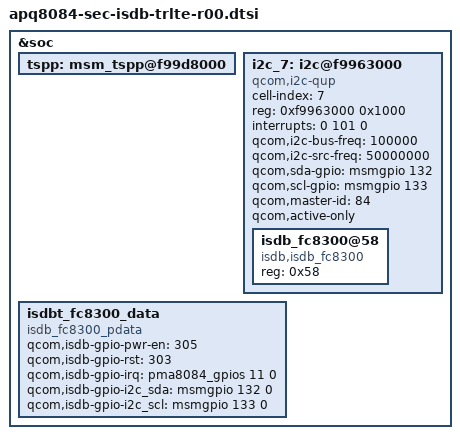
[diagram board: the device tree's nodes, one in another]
/* Copyright (c) 2012-2014, The Linux Foundation. All rights reserved.
 *
 * This program is free software; you can redistribute it and/or modify
 * it under the terms of the GNU General Public License version 2 and
 * only version 2 as published by the Free Software Foundation.
 *
 * This program is distributed in the hope that it will be useful,
 * but WITHOUT ANY WARRANTY; without even the implied warranty of
 * MERCHANTABILITY or FITNESS FOR A PARTICULAR PURPOSE.  See the
 * GNU General Public License for more details.
 */

&soc {
	tspp: msm_tspp@f99d8000 {
		status = "okay";
	};

	i2c_7: i2c@f9963000 {
		cell-index = <7>;
		compatible = "qcom,i2c-qup";
		reg = <0xf9963000 0x1000>;
		#address-cells = <1>;
		#size-cells = <0>;
		reg-names = "qup_phys_addr";
		interrupts = <0 101 0>;
		interrupt-names = "qup_err_intr";
		qcom,i2c-bus-freq = <100000>;
		qcom,i2c-src-freq = <50000000>;
		qcom,sda-gpio = <&msmgpio 132 0>;
		qcom,scl-gpio = <&msmgpio 133 0>;
		qcom,master-id = <84>;
		qcom,active-only;
		
		status = "okay";
		
		isdb_fc8300@58 {
			compatible = "isdb,isdb_fc8300";
			reg = <0x58>;
		};
	};

	isdbt_fc8300_data {
		compatible = "isdb_fc8300_pdata";
		qcom,isdb-gpio-pwr-en = <305>;
		qcom,isdb-gpio-rst = <303>;
		qcom,isdb-gpio-irq = <&pma8084_gpios 11 0>;
		qcom,isdb-gpio-i2c_sda = <&msmgpio 132 0>;
		qcom,isdb-gpio-i2c_scl = <&msmgpio 133 0>;

	};

};
